# MSP430FR5969 register map
Vendor: msp430gen; File version: v0.4.0-24-gb954137
Registers are 16-bit, read-write, reset 0x0 unless marked. A register's access mark holds for its fields unless they carry their own. Offsets are from the block's base; [hi:lo] are bit positions; {n}, {i} and the like mark numbered series.

## RTC_B_REAL_TIME_CLOCK
Base 0x000004A0
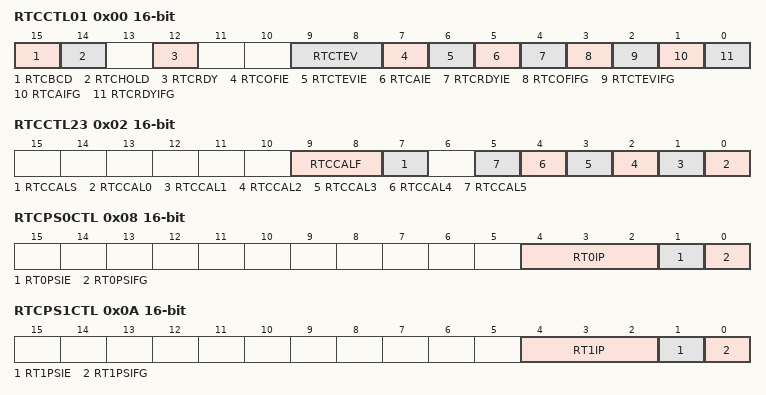
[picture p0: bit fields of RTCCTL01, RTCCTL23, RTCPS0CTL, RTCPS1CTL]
0x00 RTCCTL01 — Real Timer Control 0/1
  [15] RTCBCD — RTC BCD 0:Binary / 1:BCD
  [14] RTCHOLD
  [12] RTCRDY — RTC Ready
  [9:8] RTCTEV — RTC Time Event 1
    0=RTC Time Event: 0 (Min. changed); 1=RTC Time Event: 1 (Hour changed); 2=RTC Time Event: 2 (12:00 changed); 3=RTC Time Event: 3 (00:00 changed)
  [7] RTCOFIE — RTC 32kHz cyrstal oscillator fault interrupt enable
  [6] RTCTEVIE — RTC Time Event Interrupt Enable Flag
  [5] RTCAIE — RTC Alarm Interrupt Enable Flag
  [4] RTCRDYIE — RTC Ready Interrupt Enable Flag
  [3] RTCOFIFG — RTC 32kHz cyrstal oscillator fault interrupt flag
  [2] RTCTEVIFG — RTC Time Event Interrupt Flag
  [1] RTCAIFG — RTC Alarm Interrupt Flag
  [0] RTCRDYIFG — RTC Ready Interrupt Flag
0x02 RTCCTL23 — Real Timer Control 2/3
  [9:8] RTCCALF — RTC Calibration Frequency Bit 1
    0=RTC Calibration Frequency: No Output; 1=RTC Calibration Frequency: 512 Hz; 2=RTC Calibration Frequency: 256 Hz; 3=RTC Calibration Frequency: 1 Hz
  [7] RTCCALS — RTC Calibration Sign
  [n] RTCCAL{n} (n=0..5) — RTC Calibration Bit {n}
0x08 RTCPS0CTL — Real Timer Prescale Timer 0 Control
  [4:2] RT0IP — RTC Prescale Timer 0 Interrupt Interval Bit: 2
    0=RTC Prescale Timer 0 Interrupt Interval /2; 1=RTC Prescale Timer 0 Interrupt Interval /4; 2=RTC Prescale Timer 0 Interrupt Interval /8; 3=RTC Prescale Timer 0 Interrupt Interval /16; 4=RTC Prescale Timer 0 Interrupt Interval /32; 5=RTC Prescale Timer 0 Interrupt Interval /64; 6=RTC Prescale Timer 0 Interrupt Interval /128; 7=RTC Prescale Timer 0 Interrupt Interval /256
  [1] RT0PSIE — RTC Prescale Timer 0 Interrupt Enable Flag
  [0] RT0PSIFG — RTC Prescale Timer 0 Interrupt Flag
0x0A RTCPS1CTL — Real Timer Prescale Timer 1 Control
  [4:2] RT1IP — RTC Prescale Timer 1 Interrupt Interval Bit: 2
    0=RTC Prescale Timer 1 Interrupt Interval /2; 1=RTC Prescale Timer 1 Interrupt Interval /4; 2=RTC Prescale Timer 1 Interrupt Interval /8; 3=RTC Prescale Timer 1 Interrupt Interval /16; 4=RTC Prescale Timer 1 Interrupt Interval /32; 5=RTC Prescale Timer 1 Interrupt Interval /64; 6=RTC Prescale Timer 1 Interrupt Interval /128; 7=RTC Prescale Timer 1 Interrupt Interval /256
  [1] RT1PSIE — RTC Prescale Timer 1 Interrupt Enable Flag
  [0] RT1PSIFG — RTC Prescale Timer 1 Interrupt Flag
0x0C RTCPS — Real Timer Prescale Timer Control
0x0E RTCIV — Real Time Clock Interrupt Vector
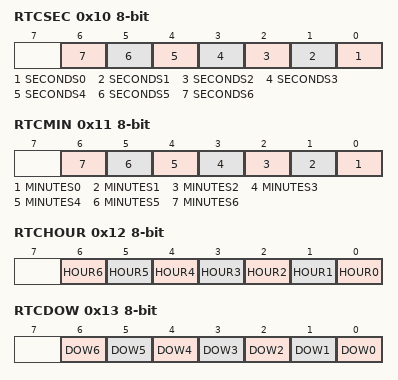
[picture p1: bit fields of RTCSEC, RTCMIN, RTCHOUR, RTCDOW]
0x10 RTCSEC 8-bit — Real Time Clock Seconds
  [n] SECONDS{n} (n=0..6) — Real Time Clock Seconds Bit: {n}
0x11 RTCMIN 8-bit — Real Time Clock Minutes
  [n] MINUTES{n} (n=0..6) — Real Time Clock Minutes Bit: {n}
0x12 RTCHOUR 8-bit — Real Time Clock Hour
  [n] HOUR{n} (n=0..6) — Real Time Clock Hour Bit: {n}
0x13 RTCDOW 8-bit — Real Time Clock Day of week
  [n] DOW{n} (n=0..6) — Real Time Clock DOW Bit: {n}
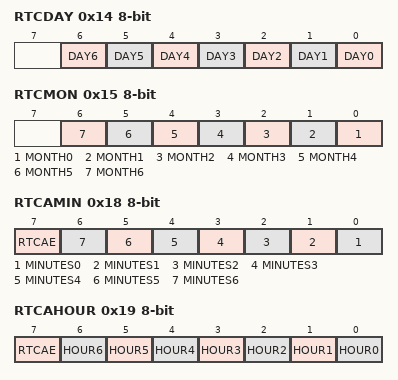
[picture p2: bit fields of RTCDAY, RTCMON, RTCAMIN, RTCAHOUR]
0x14 RTCDAY 8-bit — Real Time Clock Day
  [n] DAY{n} (n=0..6) — Real Time Clock Day Bit: {n}
0x15 RTCMON 8-bit — Real Time Clock Month
  [n] MONTH{n} (n=0..6) — Real Time Clock Month Bit: {n}
0x16 RTCYEAR — Real Time Clock Year
0x18 RTCAMIN 8-bit — Real Time Clock Alarm Min
  [7] RTCAE — Real Time Clock Alarm enable
  [n] MINUTES{n} (n=0..6) — Real Time Clock Minutes Bit: {n}
0x19 RTCAHOUR 8-bit — Real Time Clock Alarm Hour
  [7] RTCAE — Real Time Clock Alarm enable
  [n] HOUR{n} (n=0..6) — Real Time Clock Hour Bit: {n}
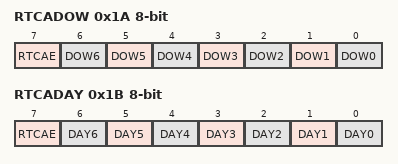
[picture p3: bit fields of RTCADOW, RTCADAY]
0x1A RTCADOW 8-bit — Real Time Clock Alarm Day of week
  [7] RTCAE — Real Time Clock Alarm enable
  [n] DOW{n} (n=0..6) — Real Time Clock DOW Bit: {n}
0x1B RTCADAY 8-bit — Real Time Clock Alarm Day
  [7] RTCAE — Real Time Clock Alarm enable
  [n] DAY{n} (n=0..6) — Real Time Clock Day Bit: {n}
0x1C BIN2BCD — Real Time Binary-to-BCD conversion register
0x1E BCD2BIN — Real Time BCD-to-binary conversion register
